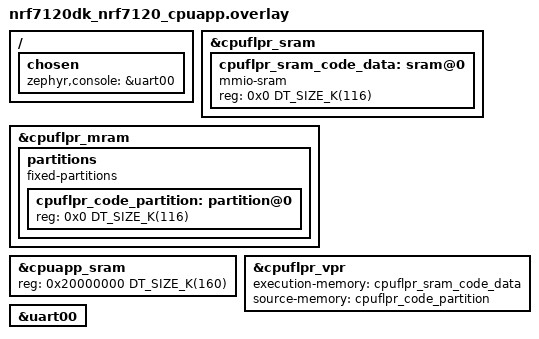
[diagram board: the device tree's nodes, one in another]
/*
 * Copyright (c) 2025 Nordic Semiconductor ASA
 *
 * SPDX-License-Identifier: LicenseRef-Nordic-5-Clause
 */

/ {
	chosen {
		zephyr,console = &uart00;
	};
};

&cpuflpr_sram {
	cpuflpr_sram_code_data: sram@0 {
		compatible = "mmio-sram";
		reg = <0x0 DT_SIZE_K(116)>;
		#address-cells = <1>;
		#size-cells = <1>;
	};
};

&cpuflpr_mram {
	partitions {
		compatible = "fixed-partitions";
		#address-cells = <1>;
		#size-cells = <1>;

		cpuflpr_code_partition: partition@0 {
			reg = <0x0 DT_SIZE_K(116)>;
		};
	};
};

&cpuapp_sram {
	reg = <0x20000000 DT_SIZE_K(160)>;
	ranges = <0x0 0x20000000 0x28000>;
};

&cpuflpr_vpr {
	status = "okay";
	execution-memory = <&cpuflpr_sram_code_data>;
	source-memory = <&cpuflpr_code_partition>;
};

&uart00 {
	status = "okay";
};

/* The same set of GPIO and GPIOTE DTS nodes are enabled in the cpuapp and the cpuflpr targets.
 * This is done to allow control over one Button and one LED in each core. The benchmark code is
 * responsible for ensuring that each core exclusively uses the individual GPIO pin and the GPIOTE
 * instance that may be used with the GPIO pin (Button).
 */
